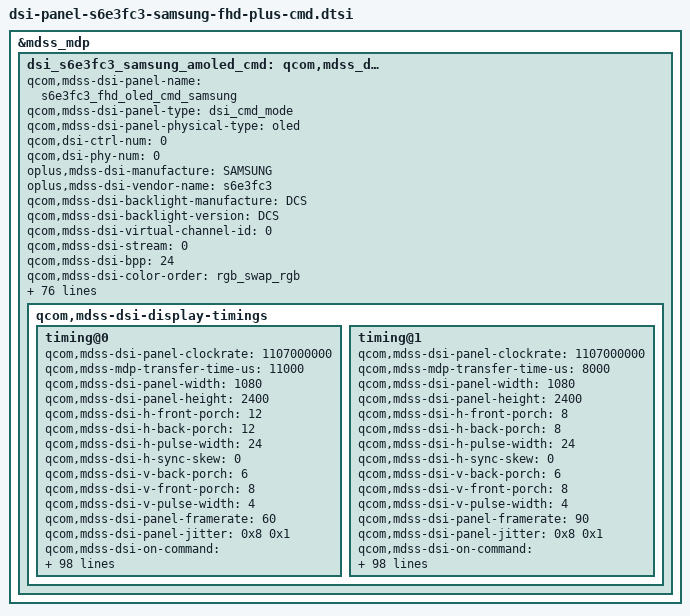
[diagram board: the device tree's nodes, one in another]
&mdss_mdp {
	dsi_s6e3fc3_samsung_amoled_cmd:
		qcom,mdss_dsi_s6e3fc3_samsung_amoled_cmd {
		qcom,mdss-dsi-panel-name = "s6e3fc3_fhd_oled_cmd_samsung";
		qcom,mdss-dsi-panel-type = "dsi_cmd_mode";
		qcom,mdss-dsi-panel-physical-type = "oled";
		qcom,dsi-ctrl-num = <0>;
		qcom,dsi-phy-num = <0>;

		oplus,mdss-dsi-manufacture = "SAMSUNG";
		oplus,mdss-dsi-vendor-name = "s6e3fc3";
		qcom,mdss-dsi-backlight-manufacture = "DCS";
		qcom,mdss-dsi-backlight-version = "DCS";
		qcom,mdss-dsi-virtual-channel-id = <0>;
		qcom,mdss-dsi-stream = <0>;
		qcom,mdss-dsi-bpp = <24>;
		qcom,mdss-dsi-color-order = "rgb_swap_rgb";
		qcom,mdss-dsi-underflow-color = <0xff>;
		qcom,mdss-dsi-border-color = <0>;
		qcom,mdss-dsi-h-sync-pulse = <0>;
		qcom,mdss-dsi-traffic-mode = "non_burst_sync_event";
		qcom,mdss-dsi-lane-map = "lane_map_0123";
		qcom,mdss-dsi-bllp-eof-power-mode;
		qcom,mdss-dsi-bllp-power-mode;
		//qcom,mdss-dsi-tx-eot-append;
		qcom,mdss-dsi-lane-0-state;
		qcom,mdss-dsi-lane-1-state;
		qcom,mdss-dsi-lane-2-state;
		qcom,mdss-dsi-lane-3-state;
		qcom,mdss-dsi-dma-trigger = "trigger_sw";
		qcom,mdss-dsi-mdp-trigger = "none";
		//qcom,mdss-dsi-lp11-init;
		qcom,mdss-dsi-bl-pmic-control-type = "bl_ctrl_dcs";
		qcom,mdss-dsi-reset-sequence = <1 10>, <0 10>, <1 10>;
		qcom,mdss-dsi-te-pin-select = <1>;
		qcom,mdss-dsi-wr-mem-start = <0x2c>;
		qcom,mdss-dsi-wr-mem-continue = <0x3c>;
		qcom,mdss-dsi-te-dcs-command = <1>;
		qcom,mdss-dsi-te-check-enable;
		qcom,mdss-dsi-te-using-te-pin;
		//qcom,mdss-dsi-te-using-wd;
		qcom,suspend-ulps-enabled;
		qcom,ulps-enabled;
		qcom,mdss-pan-physical-width-dimension = <67>;
		qcom,mdss-pan-physical-height-dimension = <149>;
		qcom,mdss-dsi-acl-mode-index = <1>;
		qcom,mdss-bl-high2bit;

		qcom,mdss-dsi-panel-seria-num-year-index = <8>;
		qcom,mdss-dsi-panel-seria-num-mon-index = <8>;
		qcom,mdss-dsi-panel-seria-num-day-index = <9>;
		qcom,mdss-dsi-panel-seria-num-hour-index = <10>;
		qcom,mdss-dsi-panel-seria-num-min-index = <11>;
		qcom,mdss-dsi-panel-seria-num-sec-index = <12>;
		qcom,mdss-dsi-panel-seria-num-msec-high-index = <13>;
		qcom,mdss-dsi-panel-seria-num-msec-low-index = <14>;
		qcom,mdss-dsi-display-timings {
			timing@0 {
				qcom,mdss-dsi-panel-clockrate = <1107000000>;
				qcom,mdss-mdp-transfer-time-us = <11000>;
				qcom,mdss-dsi-panel-width = <1080>;
				qcom,mdss-dsi-panel-height = <2400>;
				qcom,mdss-dsi-h-front-porch = <12>;
				qcom,mdss-dsi-h-back-porch = <12>;
				qcom,mdss-dsi-h-pulse-width = <24>;
				qcom,mdss-dsi-h-sync-skew = <0>;
				qcom,mdss-dsi-v-back-porch = <6>;
				qcom,mdss-dsi-v-front-porch = <8>;
				qcom,mdss-dsi-v-pulse-width = <4>;
				qcom,mdss-dsi-panel-framerate = <60>;
				qcom,mdss-dsi-panel-jitter = <0x8 0x1>;
				qcom,mdss-dsi-on-command = [
						/*PPS Setting*/
						39 01 00 00 00 00 81 9E
						11 00 00 89 30 80 09 60
						04 38 00 1E 02 1C 02 1C
						02 00 02 0E 00 20 02 E3
						00 07 00 0C 03 50 03 64
						18 00 10 F0 03 0C 20 00
						06 0B 0B 33 0E 1C 2A 38
						46 54 62 69 70 77 79 7B
						7D 7E 01 02 01 00 09 40
						09 BE 19 FC 19 FA 19 F8
						1A 38 1A 78 1A B6 2A F6
						2B 34 2B 74 3B 74 6B F4
						00 00 00 00 00 00 00 00
						00 00 00 00 00 00 00 00
						00 00 00 00 00 00 00 00
						00 00 00 00 00 00 00 00
						00 00 00 00 00 00 00 00
						15 01 00 00 00 00 02 C2 14
						15 01 00 00 00 00 02 9D 01
						/*OSC 167M*/
						39 01 00 00 00 00 03 F0 5A 5A
						39 01 00 00 00 00 03 FC 5A 5A
						39 01 00 00 00 00 03 B0 66 C5
						39 01 00 00 00 00 03 C5 00 8C
						39 01 00 00 00 00 03 B0 2A C5
						39 01 00 00 00 00 05 C5 0D 10 80 45
						39 01 00 00 00 00 03 B0 3E C5
						39 01 00 00 00 00 03 C5 4D 3D
						39 01 00 00 00 00 03 F0 A5 A5
						39 01 00 00 00 00 03 FC A5 A5
						05 01 00 00 80 00 01 11
						/* CASET/PASET Setting */
						39 01 00 00 00 00 05 2A 00 00 04 37
						39 01 00 00 00 00 05 2B 00 00 09 5F
						/* FQ CON Setting*/
						39 01 00 00 00 00 03 F0 5A 5A
						39 01 00 00 00 00 03 B0 27 F2
						15 01 00 00 00 00 02 F2 00
						39 01 00 00 00 00 03 F0 A5 A5
						/*HBM BRIGHTNESS*/
						39 01 00 00 00 00 03 F0 5A 5A
						39 01 00 00 00 00 03 B0 02 8F
						39 01 00 00 00 00 29 8F 27 05 FC 03 95 86 01 FF 15 73 FF 15 FF 37 36 61 07 07 07 1F 1F 1F 29 29 29 31 31 31 34 34 34 36 98 DA 08 04 80 00 00 22
						39 01 00 00 00 00 03 F0 A5 A5
						/* Fast discharge ON */
						39 01 00 00 00 00 03 F0 5A 5A
						39 01 00 00 00 00 03 B0 0B F4
						39 01 00 00 00 00 02 F4 1C
						39 01 00 00 00 00 03 F0 A5 A5
						/* TE vsync ON */
						15 01 00 00 00 00 02 35 00
						/*Frequency Change*/
						39 01 00 00 00 00 03 F0 5A 5A
						39 01 00 00 00 00 03 60 00 00
						39 01 00 00 00 00 02 F7 0F
						39 01 00 00 00 00 03 F0 A5 A5
						/*HBM PROTECT*/
						39 01 00 00 00 00 03 F0 5A 5A
						39 01 00 00 00 00 04 91 02 01 00
						39 01 00 00 00 00 05 90 00 0F 1C 08
						39 01 00 00 00 00 03 B0 28 F2
						39 01 00 00 00 00 02 F2 CE
						39 01 00 00 00 00 04 B0 02 02 CB
						39 01 00 00 00 00 03 CB 02 02
						39 01 00 00 00 00 04 B0 00 28 F2
						39 01 00 00 00 00 02 F2 C6
						39 01 00 00 00 00 03 F0 A5 A5
						15 01 00 00 00 00 02 53 20
				];

				qcom,mdss-dsi-off-command = [
						05 01 00 00 0A 00 02 28 00
						05 01 00 00 96 00 02 10 00
				];

				qcom,mdss-dsi-post-on-backlight = [
						39 01 00 00 00 00 03 F0 5A 5A
						39 01 00 00 00 00 03 F0 A5 A5
						05 01 00 00 00 00 01 29
				];

				qcom,mdss-dsi-timing-switch-command = [
						/* 60hz Transition */
						39 01 00 00 00 00 03 F0 5A 5A
						39 01 00 00 00 00 03 60 00 00
						39 01 00 00 00 00 02 F7 0F
						39 01 00 00 00 00 03 F0 A5 A5
				];

				qcom,mdss-dsi-lp1-command = [
						05 01 00 00 00 00 01 28
						39 01 00 00 00 00 03 F0 5A 5A
						39 01 00 00 00 00 02 91 01
						15 01 00 00 00 00 02 53 24
						15 01 00 00 00 00 02 BB 1D
						39 01 00 00 00 00 03 F0 A5 A5
				];

				qcom,mdss-dsi-aod-high-mode-command = [
						15 01 00 00 00 00 02 53 24
				];

				qcom,mdss-dsi-aod-low-mode-command = [
						15 01 00 00 00 00 02 53 25
				];

				qcom,mdss-dsi-nolp-command = [
						39 00 00 00 00 00 03 F0 5A 5A
						39 00 00 00 00 00 03 B0 02 90
						15 00 00 00 00 00 02 90 1C
						39 00 00 00 00 00 05 BB 11 0C 50 10
						39 00 00 00 00 00 02 91 02
						15 00 00 00 00 00 02 53 20
						39 01 00 00 00 00 03 F0 A5 A5
				];

				qcom,mdss-dsi-aod-hbm-on-command = [
						/* AOD off */
						39 00 00 00 00 00 03 F0 5A 5A
						39 00 00 00 00 00 05 BB 11 0C 50 10
						39 00 00 00 00 00 02 91 02
						15 00 00 00 00 00 02 53 20
						39 00 00 00 00 00 03 F0 A5 A5
						/* HBM Mode ON */
						39 00 00 00 00 00 03 F0 5A 5A
						39 00 00 00 00 00 03 B0 02 90
						15 00 00 00 00 00 02 90 14
						/* 0xE0 Normal transition */
						39 00 00 00 00 00 02 53 E0
						39 00 00 00 00 00 03 51 0F FF
						39 01 00 00 00 00 03 F0 A5 A5
				];

				qcom,mdss-dsi-aod-hbm-off-command = [
						/*HBM OFF */
						39 01 00 00 00 00 03 F0 5A 5A
						39 01 00 00 00 00 03 B0 02 90
						15 01 00 00 00 00 02 90 1C
						15 01 00 00 00 00 02 53 24
						39 01 00 00 00 00 03 F0 A5 A5
						/*AOD on */
						39 01 00 00 00 00 03 F0 5A 5A
						39 01 00 00 00 00 02 91 01
						15 01 00 00 00 00 02 53 24
						15 01 00 00 00 00 02 BB 1D
						39 01 00 00 00 00 03 F0 A5 A5
				];

				qcom,mdss-dsi-hbm-on-command = [
						/* HBM Mode ON */
						39 01 00 00 00 00 03 F0 5A 5A
						39 01 00 00 00 00 03 B0 02 90
						15 01 00 00 00 00 02 90 14
						/* 0xE0 Normal transition */
						15 01 00 00 00 00 02 53 E0
						39 01 00 00 00 00 03 51 0F FF
						39 01 00 00 00 00 03 F0 A5 A5
				];
				qcom,mdss-dsi-normal-hbm-on-command = [
						/* HBM Mode ON */
						39 01 00 00 00 00 03 F0 5A 5A
						39 01 00 00 00 00 03 B0 02 90
						15 01 00 00 00 00 02 90 14
						/* 0xE0 Normal transition */
						15 01 00 00 00 00 02 53 E0
						39 01 00 00 00 00 03 51 0F FF
						39 01 00 00 00 00 03 F0 A5 A5
				];
				qcom,mdss-dsi-hbm-off-command = [
						/*HBM OFF */
						39 01 00 00 00 00 03 F0 5A 5A
						39 01 00 00 00 00 03 B0 02 90
						15 01 00 00 00 00 02 90 1C
						15 01 00 00 00 00 02 53 20
						39 01 00 00 0D 00 03 F0 A5 A5
				];
				qcom,mdss-dsi-hbm-enter-switch-command = [
						39 01 00 00 00 00 03 F0 5A 5A
						39 01 00 00 11 00 03 51 07 FF
						39 00 00 00 00 00 03 91 02 00
						15 00 00 00 00 00 02 53 E0
						39 01 00 00 00 00 03 51 08 00
						39 01 00 00 00 00 03 F0 A5 A5
				];
				qcom,mdss-dsi-hbm-exit-switch-command = [
						39 01 00 00 00 00 03 F0 5A 5A
						15 00 00 00 00 00 02 53 20
						39 01 00 00 11 00 03 51 07 FF
						39 00 00 00 00 00 03 91 02 01
						39 01 00 00 00 00 03 F0 A5 A5
				];
				qcom,mdss-dsi-seed-0-command = [
						/* SEED CRC Setting */
						39 01 00 00 00 00 03 F0 5A 5A
						39 01 00 00 00 00 02 5D 86
						39 01 00 00 00 00 04 72 2C 21 00
						39 01 00 00 00 00 02 F8 00
						/* SEED CRC ON */
						39 01 00 00 00 00 02 62 00
						39 01 00 00 00 00 03 B0 2B 62
						39 01 00 00 00 00 16 62 FF 00 00 00 FF 00 00 00 FF 00 FF FF FF 00 FF FF FF 00 FF FF FF
						39 01 00 00 0B 00 04 72 2C 01 00
						39 01 00 00 00 00 03 F0 A5 A5
				];
				qcom,mdss-dsi-seed-1-command = [
						/* SEED CRC Setting */
						39 01 00 00 00 00 03 F0 5A 5A
						39 01 00 00 00 00 02 5D 86
						39 01 00 00 00 00 04 72 2C 21 00
						39 01 00 00 00 00 02 F8 00
						/* SEED CRC ON */
						39 01 00 00 00 00 02 62 00
						39 01 00 00 00 00 03 B0 2B 62
						39 01 00 00 00 00 16 62 D8 00 04 00 FF 02 00 00 FF 18 FF E4 FB 00 F0 F6 EA 01 FF FF FF
						39 01 00 00 0B 00 04 72 2C 01 00
						39 01 00 00 00 00 03 F0 A5 A5
				];
				qcom,mdss-dsi-seed-2-command = [
						/* SEED CRC Setting */
						39 01 00 00 00 00 03 F0 5A 5A
						39 01 00 00 00 00 02 5D 86
						39 01 00 00 00 00 04 72 2C 21 00
						39 01 00 00 00 00 02 F8 00
						/* SEED CRC ON */
						39 01 00 00 00 00 02 62 00
						39 01 00 00 00 00 03 B0 2B 62
						39 01 00 00 00 00 16 62 D8 00 04 00 FF 02 00 00 FF 18 FF E4 FB 00 F0 F6 EA 01 FF FF FF
						39 01 00 00 0B 00 04 72 2C 01 00
						39 01 00 00 00 00 03 F0 A5 A5
				];
				qcom,mdss-dsi-acl-command = [
						15 01 00 00 00 00 02 55 00
				];

				qcom,mdss-dsi-osc-clk-mode0-command = [
						/*OSC 167M*/
						39 01 00 00 00 00 03 F0 5A 5A
						39 01 00 00 00 00 03 FC 5A 5A
						39 01 00 00 00 00 03 B0 66 C5
						39 01 00 00 00 00 03 C5 00 8C
						39 01 00 00 00 00 03 B0 2A C5
						39 01 00 00 00 00 05 C5 0D 10 80 45
						39 01 00 00 00 00 03 B0 3E C5
						39 01 00 00 00 00 03 C5 4D 3D
						39 01 00 00 00 00 03 F0 A5 A5
						39 01 00 00 00 00 03 FC A5 A5
				];

				qcom,mdss-dsi-osc-clk-mode1-command = [
						/*OSC 169M*/
						39 01 00 00 00 00 03 F0 5A 5A
						39 01 00 00 00 00 03 FC 5A 5A
						39 01 00 00 00 00 03 B0 66 C5
						39 01 00 00 00 00 03 C5 00 8C
						39 01 00 00 00 00 03 B0 2A C5
						39 01 00 00 00 00 05 C5 0D 10 80 45
						39 01 00 00 00 00 03 B0 3E C5
						39 01 00 00 00 00 03 C5 4E 2A
						39 01 00 00 00 00 03 F0 A5 A5
						39 01 00 00 00 00 03 FC A5 A5
				];

				qcom,mdss-dsi-panel-register-read-command = [
						06 01 00 00 00 00 01 D8
				];

				qcom,mdss-dsi-panel-level2-key-enable-command = [
						39 01 00 00 00 00 03 F0 5A 5A
				];

				qcom,mdss-dsi-panel-level2-key-disable-command = [
						39 01 00 00 00 00 03 F0 A5 A5
				];


				qcom,mdss-dsi-on-command-state = "dsi_lp_mode";
				qcom,mdss-dsi-off-command-state = "dsi_hs_mode";
				qcom,mdss-dsi-post-on-backlight-state = "dsi_hs_mode";
				qcom,mdss-dsi-timing-switch-command-state = "dsi_lp_mode";
				qcom,mdss-dsi-aod-high-mode-command-state ="dsi_lp_mode";
				qcom,mdss-dsi-aod-low-mode-command-state ="dsi_lp_mode";
				qcom,mdss-dsi-nolp-command-state = "dsi_lp_mode";
				qcom,mdss-dsi-aod-hbm-on-command-state = "dsi_lp_mode";
				qcom,mdss-dsi-aod-hbm-off-command-state = "dsi_hs_mode";
				qcom,mdss-dsi-hbm-on-command-state = "dsi_hs_mode";
				qcom,mdss-dsi-hbm-off-command-state = "dsi_hs_mode";
				qcom,mdss-dsi-panel-hbm-brightness-on-command-state = "dsi_hs_mode";
				qcom,mdss-dsi-panel-hbm-brightness-off-command-state = "dsi_hs_mode";
				qcom,mdss-dsi-seed-0-command-state = "dsi_hs_mode";
				qcom,mdss-dsi-seed-1-command-state = "dsi_hs_mode";
				qcom,mdss-dsi-seed-2-command-state = "dsi_hs_mode";
				qcom,mdss-dsi-acl-command-state = "dsi_lp_mode";
				qcom,mdss-dsi-osc-clk-mode0-command-state = "dsi_lp_mode";
				qcom,mdss-dsi-osc-clk-mode1-command-state = "dsi_lp_mode";
				qcom,mdss-dsi-panel-register-read-command-state = "dsi_lp_mode";
				qcom,mdss-dsi-panel-level2-key-enable-command-state = "dsi_lp_mode";
				qcom,mdss-dsi-panel-level2-key-disable-command-state = "dsi_lp_mode";


				qcom,compression-mode = "dsc";
				qcom,mdss-dsc-slice-height = <30>;
				qcom,mdss-dsc-slice-width = <540>;
				qcom,mdss-dsc-slice-per-pkt = <2>;
				qcom,mdss-dsc-bit-per-component = <8>;
				qcom,mdss-dsc-bit-per-pixel = <8>;
				qcom,mdss-dsc-block-prediction-enable;
			};
			timing@1 {
				qcom,mdss-dsi-panel-clockrate = <1107000000>;
				qcom,mdss-mdp-transfer-time-us = <8000>;
				qcom,mdss-dsi-panel-width = <1080>;
				qcom,mdss-dsi-panel-height = <2400>;
				qcom,mdss-dsi-h-front-porch = <8>;
				qcom,mdss-dsi-h-back-porch = <8>;
				qcom,mdss-dsi-h-pulse-width = <24>;
				qcom,mdss-dsi-h-sync-skew = <0>;
				qcom,mdss-dsi-v-back-porch = <6>;
				qcom,mdss-dsi-v-front-porch = <8>;
				qcom,mdss-dsi-v-pulse-width = <4>;
				qcom,mdss-dsi-panel-framerate = <90>;
				qcom,mdss-dsi-panel-jitter = <0x8 0x1>;
				qcom,mdss-dsi-on-command = [
						/*PPS Setting*/
						39 01 00 00 00 00 81 9E
						11 00 00 89 30 80 09 60
						04 38 00 1E 02 1C 02 1C
						02 00 02 0E 00 20 02 E3
						00 07 00 0C 03 50 03 64
						18 00 10 F0 03 0C 20 00
						06 0B 0B 33 0E 1C 2A 38
						46 54 62 69 70 77 79 7B
						7D 7E 01 02 01 00 09 40
						09 BE 19 FC 19 FA 19 F8
						1A 38 1A 78 1A B6 2A F6
						2B 34 2B 74 3B 74 6B F4
						00 00 00 00 00 00 00 00
						00 00 00 00 00 00 00 00
						00 00 00 00 00 00 00 00
						00 00 00 00 00 00 00 00
						00 00 00 00 00 00 00 00
						15 01 00 00 00 00 02 C2 14
						15 01 00 00 00 00 02 9D 01
						/*OSC 167M*/
						39 01 00 00 00 00 03 F0 5A 5A
						39 01 00 00 00 00 03 FC 5A 5A
						39 01 00 00 00 00 03 B0 66 C5
						39 01 00 00 00 00 03 C5 00 8C
						39 01 00 00 00 00 03 B0 2A C5
						39 01 00 00 00 00 05 C5 0D 10 80 45
						39 01 00 00 00 00 03 B0 3E C5
						39 01 00 00 00 00 03 C5 4D 3D
						39 01 00 00 00 00 03 F0 A5 A5
						39 01 00 00 00 00 03 FC A5 A5
						05 01 00 00 80 00 01 11
						/* CASET/PASET Setting */
						39 01 00 00 00 00 05 2A 00 00 04 37
						39 01 00 00 00 00 05 2B 00 00 09 5F
						/* FQ CON Setting*/
						39 01 00 00 00 00 03 F0 5A 5A
						39 01 00 00 00 00 03 B0 27 F2
						15 01 00 00 00 00 02 F2 00
						39 01 00 00 00 00 03 F0 A5 A5
						/*HBM BRIGHTNESS*/
						39 01 00 00 00 00 03 F0 5A 5A
						39 01 00 00 00 00 03 B0 02 8F
						39 01 00 00 00 00 29 8F 27 05 FC 03 95 86 01 FF 15 73 FF 15 FF 37 36 61 07 07 07 1F 1F 1F 29 29 29 31 31 31 34 34 34 36 98 DA 08 04 80 00 00 22
						39 01 00 00 00 00 03 F0 A5 A5
						/* Fast discharge ON */
						39 01 00 00 00 00 03 F0 5A 5A
						39 01 00 00 00 00 03 B0 0B F4
						39 01 00 00 00 00 02 F4 1C
						39 01 00 00 00 00 03 F0 A5 A5
						/* TE vsync ON */
						15 01 00 00 00 00 02 35 00
						/*Frequency Change*/
						39 01 00 00 00 00 03 F0 5A 5A
						39 01 00 00 00 00 03 60 08 00
						39 01 00 00 00 00 02 F7 0F
						39 01 00 00 00 00 03 F0 A5 A5
						/*HBM PROTECT*/
						39 01 00 00 00 00 03 F0 5A 5A
						39 01 00 00 00 00 04 91 02 01 00
						39 01 00 00 00 00 05 90 00 0F 1C 08
						39 01 00 00 00 00 03 B0 28 F2
						39 01 00 00 00 00 02 F2 CE
						39 01 00 00 00 00 04 B0 02 02 CB
						39 01 00 00 00 00 03 CB 02 02
						39 01 00 00 00 00 04 B0 00 28 F2
						39 01 00 00 00 00 02 F2 C6
						39 01 00 00 00 00 03 F0 A5 A5
						15 01 00 00 00 00 02 53 20
				];

				qcom,mdss-dsi-off-command = [
						05 01 00 00 0A 00 02 28 00
						05 01 00 00 96 00 02 10 00
				];

				qcom,mdss-dsi-post-on-backlight = [
						39 01 00 00 00 00 03 F0 5A 5A
						39 01 00 00 00 00 03 F0 A5 A5
						05 01 00 00 00 00 01 29
				];

				qcom,mdss-dsi-timing-switch-command = [
						/* 90hz Transition */
						39 01 00 00 00 00 03 F0 5A 5A
						39 01 00 00 00 00 03 60 08 00
						39 01 00 00 00 00 02 F7 0F
						39 01 00 00 00 00 03 F0 A5 A5
				];

				qcom,mdss-dsi-lp1-command = [
						05 01 00 00 00 00 01 28
						39 01 00 00 00 00 03 F0 5A 5A
						39 01 00 00 00 00 02 91 01
						15 01 00 00 00 00 02 53 24
						15 01 00 00 00 00 02 BB 1D
						39 01 00 00 00 00 03 F0 A5 A5
				];

				qcom,mdss-dsi-aod-high-mode-command = [
						15 01 00 00 00 00 02 53 24
				];

				qcom,mdss-dsi-aod-low-mode-command = [
						15 01 00 00 00 00 02 53 25
				];

				qcom,mdss-dsi-nolp-command = [
						39 00 00 00 00 00 03 F0 5A 5A
						39 00 00 00 00 00 03 B0 02 90
						15 00 00 00 00 00 02 90 1C
						39 00 00 00 00 00 05 BB 11 0C 50 10
						39 00 00 00 00 00 02 91 02
						15 00 00 00 00 00 02 53 20
						39 01 00 00 00 00 03 F0 A5 A5
				];

				qcom,mdss-dsi-aod-hbm-on-command = [
						/* AOD off */
						39 00 00 00 00 00 03 F0 5A 5A
						39 00 00 00 00 00 05 BB 11 0C 50 10
						39 00 00 00 00 00 02 91 02
						15 00 00 00 00 00 02 53 20
						39 00 00 00 00 00 03 F0 A5 A5
						/* HBM Mode ON */
						39 00 00 00 00 00 03 F0 5A 5A
						39 00 00 00 00 00 03 B0 02 90
						15 00 00 00 00 00 02 90 14
						/* 0xE0 Normal transition */
						39 00 00 00 00 00 02 53 E0
						39 00 00 00 00 00 03 51 0F FF
						39 01 00 00 00 00 03 F0 A5 A5
				];

				qcom,mdss-dsi-aod-hbm-off-command = [
						/*HBM OFF */
						39 01 00 00 00 00 03 F0 5A 5A
						39 01 00 00 00 00 03 B0 02 90
						15 01 00 00 00 00 02 90 1C
						15 01 00 00 00 00 02 53 24
						39 01 00 00 00 00 03 F0 A5 A5
						/*AOD on */
						39 01 00 00 00 00 03 F0 5A 5A
						39 01 00 00 00 00 02 91 01
						15 01 00 00 00 00 02 53 24
						15 01 00 00 00 00 02 BB 1D
						39 01 00 00 00 00 03 F0 A5 A5
				];

				qcom,mdss-dsi-hbm-on-command = [
						/* HBM Mode ON */
						39 01 00 00 00 00 03 F0 5A 5A
						39 01 00 00 00 00 03 B0 02 90
						15 01 00 00 00 00 02 90 14
						/* 0xE0 Normal transition */
						15 01 00 00 00 00 02 53 E0
						39 01 00 00 00 00 03 51 0F FF
						39 01 00 00 00 00 03 F0 A5 A5
				];
				qcom,mdss-dsi-normal-hbm-on-command = [
						/* HBM Mode ON */
						39 01 00 00 00 00 03 F0 5A 5A
						39 01 00 00 00 00 03 B0 02 90
						15 01 00 00 00 00 02 90 14
						/* 0xE0 Normal transition */
						15 01 00 00 00 00 02 53 E0
						39 01 00 00 00 00 03 51 0F FF
						39 01 00 00 00 00 03 F0 A5 A5
				];
				qcom,mdss-dsi-hbm-off-command = [
						/*HBM OFF */
						39 01 00 00 00 00 03 F0 5A 5A
						39 01 00 00 00 00 03 B0 02 90
						15 01 00 00 00 00 02 90 1C
						15 01 00 00 00 00 02 53 20
						39 01 00 00 0D 00 03 F0 A5 A5
				];
				qcom,mdss-dsi-hbm-enter-switch-command = [
						39 01 00 00 00 00 03 F0 5A 5A
						39 01 00 00 0C 00 03 51 07 FF
						39 00 00 00 00 00 03 91 02 00
						15 00 00 00 00 00 02 53 E0
						39 01 00 00 00 00 03 51 08 00
						39 01 00 00 00 00 03 F0 A5 A5
				];
				qcom,mdss-dsi-hbm-exit-switch-command = [
						39 01 00 00 00 00 03 F0 5A 5A
						15 00 00 00 00 00 02 53 20
						39 01 00 00 0C 00 03 51 07 FF
						39 00 00 00 00 00 03 91 02 01
						39 01 00 00 00 00 03 F0 A5 A5
				];
				qcom,mdss-dsi-seed-0-command = [
						/* SEED CRC Setting */
						39 01 00 00 00 00 03 F0 5A 5A
						39 01 00 00 00 00 02 5D 86
						39 01 00 00 00 00 04 72 2C 21 00
						39 01 00 00 00 00 02 F8 00
						/* SEED CRC ON */
						39 01 00 00 00 00 02 62 00
						39 01 00 00 00 00 03 B0 2B 62
						39 01 00 00 00 00 16 62 FF 00 00 00 FF 00 00 00 FF 00 FF FF FF 00 FF FF FF 00 FF FF FF
						39 01 00 00 0B 00 04 72 2C 01 00
						39 01 00 00 00 00 03 F0 A5 A5
				];
				qcom,mdss-dsi-seed-1-command = [
						/* SEED CRC Setting */
						39 01 00 00 00 00 03 F0 5A 5A
						39 01 00 00 00 00 02 5D 86
						39 01 00 00 00 00 04 72 2C 21 00
						39 01 00 00 00 00 02 F8 00
						/* SEED CRC ON */
						39 01 00 00 00 00 02 62 00
						39 01 00 00 00 00 03 B0 2B 62
						39 01 00 00 00 00 16 62 D8 00 04 00 FF 02 00 00 FF 18 FF E4 FB 00 F0 F6 EA 01 FF FF FF
						39 01 00 00 0B 00 04 72 2C 01 00
						39 01 00 00 00 00 03 F0 A5 A5
				];
				qcom,mdss-dsi-seed-2-command = [
						/* SEED CRC Setting */
						39 01 00 00 00 00 03 F0 5A 5A
						39 01 00 00 00 00 02 5D 86
						39 01 00 00 00 00 04 72 2C 21 00
						39 01 00 00 00 00 02 F8 00
						/* SEED CRC ON */
						39 01 00 00 00 00 02 62 00
						39 01 00 00 00 00 03 B0 2B 62
						39 01 00 00 00 00 16 62 D8 00 04 00 FF 02 00 00 FF 18 FF E4 FB 00 F0 F6 EA 01 FF FF FF
						39 01 00 00 0B 00 04 72 2C 01 00
						39 01 00 00 00 00 03 F0 A5 A5
				];
				qcom,mdss-dsi-acl-command = [
						15 01 00 00 00 00 02 55 00
				];

				qcom,mdss-dsi-osc-clk-mode0-command = [
						/*OSC 167M*/
						39 01 00 00 00 00 03 F0 5A 5A
						39 01 00 00 00 00 03 FC 5A 5A
						39 01 00 00 00 00 03 B0 66 C5
						39 01 00 00 00 00 03 C5 00 8C
						39 01 00 00 00 00 03 B0 2A C5
						39 01 00 00 00 00 05 C5 0D 10 80 45
						39 01 00 00 00 00 03 B0 3E C5
						39 01 00 00 00 00 03 C5 4D 3D
						39 01 00 00 00 00 03 F0 A5 A5
						39 01 00 00 00 00 03 FC A5 A5
				];

				qcom,mdss-dsi-osc-clk-mode1-command = [
						/*OSC 169M*/
						39 01 00 00 00 00 03 F0 5A 5A
						39 01 00 00 00 00 03 FC 5A 5A
						39 01 00 00 00 00 03 B0 66 C5
						39 01 00 00 00 00 03 C5 00 8C
						39 01 00 00 00 00 03 B0 2A C5
						39 01 00 00 00 00 05 C5 0D 10 80 45
						39 01 00 00 00 00 03 B0 3E C5
						39 01 00 00 00 00 03 C5 4E 2A
						39 01 00 00 00 00 03 F0 A5 A5
						39 01 00 00 00 00 03 FC A5 A5
				];

				qcom,mdss-dsi-panel-register-read-command = [
						06 01 00 00 00 00 01 D8
				];

				qcom,mdss-dsi-panel-level2-key-enable-command = [
						39 01 00 00 00 00 03 F0 5A 5A
				];

				qcom,mdss-dsi-panel-level2-key-disable-command = [
						39 01 00 00 00 00 03 F0 A5 A5
				];


				qcom,mdss-dsi-on-command-state = "dsi_lp_mode";
				qcom,mdss-dsi-off-command-state = "dsi_hs_mode";
				qcom,mdss-dsi-post-on-backlight-state = "dsi_hs_mode";
				qcom,mdss-dsi-timing-switch-command-state = "dsi_lp_mode";
				qcom,mdss-dsi-aod-high-mode-command-state ="dsi_lp_mode";
				qcom,mdss-dsi-aod-low-mode-command-state ="dsi_lp_mode";
				qcom,mdss-dsi-nolp-command-state = "dsi_lp_mode";
				qcom,mdss-dsi-aod-hbm-on-command-state = "dsi_lp_mode";
				qcom,mdss-dsi-aod-hbm-off-command-state = "dsi_hs_mode";
				qcom,mdss-dsi-hbm-on-command-state = "dsi_hs_mode";
				qcom,mdss-dsi-hbm-off-command-state = "dsi_hs_mode";
				qcom,mdss-dsi-panel-hbm-brightness-on-command-state = "dsi_hs_mode";
				qcom,mdss-dsi-panel-hbm-brightness-off-command-state = "dsi_hs_mode";
				qcom,mdss-dsi-seed-0-command-state = "dsi_hs_mode";
				qcom,mdss-dsi-seed-1-command-state = "dsi_hs_mode";
				qcom,mdss-dsi-seed-2-command-state = "dsi_hs_mode";
				qcom,mdss-dsi-acl-command-state = "dsi_lp_mode";
				qcom,mdss-dsi-osc-clk-mode0-command-state = "dsi_lp_mode";
				qcom,mdss-dsi-osc-clk-mode1-command-state = "dsi_lp_mode";
				qcom,mdss-dsi-panel-register-read-command-state = "dsi_lp_mode";
				qcom,mdss-dsi-panel-level2-key-enable-command-state = "dsi_lp_mode";
				qcom,mdss-dsi-panel-level2-key-disable-command-state = "dsi_lp_mode";


				qcom,compression-mode = "dsc";
				qcom,mdss-dsc-slice-height = <30>;
				qcom,mdss-dsc-slice-width = <540>;
				qcom,mdss-dsc-slice-per-pkt = <2>;
				qcom,mdss-dsc-bit-per-component = <8>;
				qcom,mdss-dsc-bit-per-pixel = <8>;
				qcom,mdss-dsc-block-prediction-enable;
			};
		};
	};
};
&dsi_s6e3fc3_samsung_amoled_cmd {
	qcom,panel-supply-entries = <&dsi_panel_pwr_supply_vout>;
	qcom,mdss-dsi-bl-pmic-control-type = "bl_ctrl_dcs";
	qcom,bl-update-flag = "delay_until_first_frame";
	qcom,mdss-dsi-bl-min-level = <1>;
	qcom,mdss-dsi-bl-max-level = <4095>;
	qcom,mdss-dsi-bl-normal-max-level = <2047>;
	qcom,mdss-brightness-max-level = <4095>;
	qcom,mdss-brightness-normal-max-level = <2047>;
	qcom,platform-te-gpio = <&tlmm 23 0>;
	qcom,platform-reset-gpio = <&pm6150l_gpios 3 0>;
	qcom,vddr-gpio = <&pm7250b_gpios 10 0>;
	qcom,esd-check-enabled;
	qcom,mdss-dsi-panel-status-check-mode = "reg_read";
	qcom,mdss-dsi-panel-status-command = [06 01 00 01 05 00 02 0A 00
						06 01 00 01 05 00 02 03 00
						06 01 00 01 05 00 02 05 00];
	qcom,mdss-dsi-panel-status-command-state = "dsi_lp_mode";
	qcom,mdss-dsi-panel-status-value = <0x9F 0x01 0x00>;
	qcom,mdss-dsi-panel-status-read-length = <1 1 1>;
	oplus,osc-support;
	oplus,mdss-dsi-osc-clk-mode0-rate = <167000>;
	oplus,mdss-dsi-osc-clk-mode1-rate = <169000>;
	oplus,dsi-fod-brightness =  <4 0xeb>,
				<10 0xe7>,
				<20 0xe3>,
				<42 0xd9>,
				<60 0xd3>,
				<90 0xcb>,
				<140 0xbf>,
				<200 0xb5>,
				<300 0xa7>,
				<450 0x96>,
				<600 0x88>,
				<750 0x7b>,
				<900 0x6f>,
				<1050 0x64>,
				<1200 0x5b>,
				<1400 0x4e>,
				<1606 0x43>,
				<1795 0x38>,
				<2047 0x2a>;

	qcom,dsi-select-clocks = "mux_byte_clk0", "mux_pixel_clk0";
	qcom,mdss-dsi-t-clk-post = <0x0E>;
	qcom,mdss-dsi-t-clk-pre = <0x3B>;
	qcom,dynamic-mode-switch-enabled;
	qcom,dynamic-mode-switch-type = "dynamic-resolution-switch-immediate";
	qcom,mdss-dsi-display-timings {
		timing@0 {
			qcom,mdss-dsi-panel-phy-timings = [00 24 0A 0A 26 24 0A 0A 09 02 04 00];
			qcom,display-topology = <1 1 1>;
			qcom,default-topology-index = <0>;
		};
		timing@1 {
			qcom,mdss-dsi-panel-phy-timings = [00 24 0A 0A 26 24 0A 0A 09 02 04 00];
			qcom,display-topology = <1 1 1>;
			qcom,default-topology-index = <0>;
		};
	};
};
